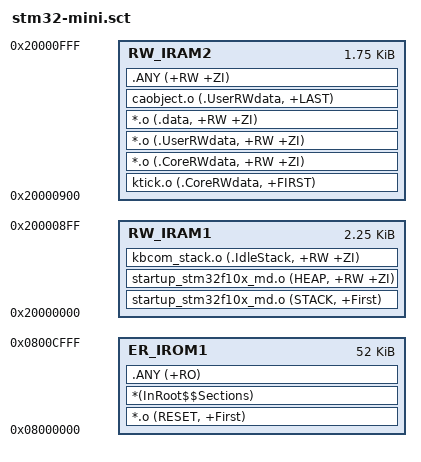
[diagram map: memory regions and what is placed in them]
; *************************************************************
; *** Scatter-Loading Description File generated by uVision ***
; *************************************************************

LR_IROM1 0x08000000 0x0000D000  {    ; load region size_region
  ER_IROM1 0x08000000 0x0000D000  {  ; load address = execution address
   *.o (RESET, +First)
   *(InRoot$$Sections)
   .ANY (+RO)
  }
  RW_IRAM1 0x20000000 0x00000900  {  ; RW data
   startup_stm32f10x_md.o (STACK, +First)
   startup_stm32f10x_md.o (HEAP, +RW +ZI)
   kbcom_stack.o (.IdleStack, +RW +ZI)
;   kbstm32_stack.o (.CoreStack, +RW +ZI)
  }
  RW_IRAM2 0x20000900 0x00000700  {  ; RW data
   ktick.o (.CoreRWdata, +FIRST)
   *.o (.CoreRWdata, +RW +ZI)
   *.o (.UserRWdata, +RW +ZI)
   *.o (.data, +RW +ZI)
   caobject.o (.UserRWdata, +LAST)
   .ANY (+RW +ZI)
  }
}

